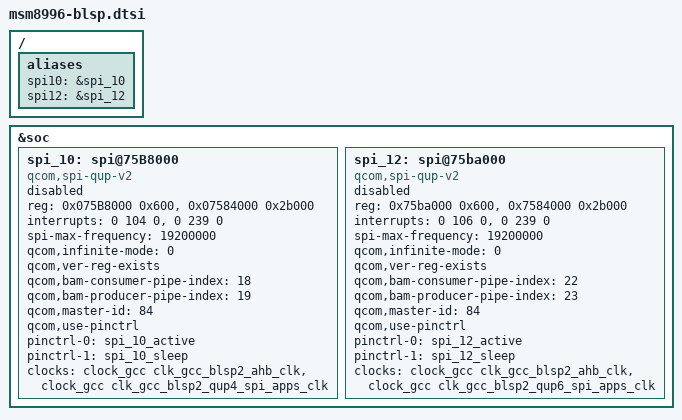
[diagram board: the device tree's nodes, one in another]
/*
 * Copyright (c) 2015, The Linux Foundation. All rights reserved.
 *
 * This program is free software; you can redistribute it and/or modify
 * it under the terms of the GNU General Public License version 2 and
 * only version 2 as published by the Free Software Foundation.
 *
 * This program is distributed in the hope that it will be useful,
 * but WITHOUT ANY WARRANTY; without even the implied warranty of
 * MERCHANTABILITY or FITNESS FOR A PARTICULAR PURPOSE.  See the
 * GNU General Public License for more details.
 */
/ {
	aliases {
		spi10 = &spi_10;
		spi12 = &spi_12;
	};
};

&soc {
	spi_10: spi@75B8000 { /* BLSP2 QUP4 */
		compatible = "qcom,spi-qup-v2";
		#address-cells = <1>;
		#size-cells = <0>;
		reg-names = "spi_physical", "spi_bam_physical";
		reg = <0x075B8000 0x600>,
		      <0x07584000 0x2b000>;
		interrupt-names = "spi_irq", "spi_bam_irq";
		interrupts = <0 104 0>, <0 239 0>;
		spi-max-frequency = <19200000>;
		qcom,infinite-mode = <0>;
		qcom,ver-reg-exists;

		qcom,bam-consumer-pipe-index = <18>;
		qcom,bam-producer-pipe-index = <19>;
		qcom,master-id = <84>;
		qcom,use-pinctrl;
		pinctrl-names = "spi_default", "spi_sleep";
		pinctrl-0 = <&spi_10_active>;
		pinctrl-1 = <&spi_10_sleep>;
		clock-names = "iface_clk", "core_clk";
		clocks = <&clock_gcc clk_gcc_blsp2_ahb_clk>,
			 <&clock_gcc clk_gcc_blsp2_qup4_spi_apps_clk>;
		status = "disabled";
	};

	spi_12: spi@75ba000 { /* BLSP2 QUP6 */
		compatible = "qcom,spi-qup-v2";
		#address-cells = <1>;
		#size-cells = <0>;
		reg-names = "spi_physical", "spi_bam_physical";
		reg = <0x75ba000 0x600>,
		      <0x7584000 0x2b000>;
		interrupt-names = "spi_irq", "spi_bam_irq";
		interrupts = <0 106 0>, <0 239 0>;
		spi-max-frequency = <19200000>;
		qcom,infinite-mode = <0>;
		qcom,ver-reg-exists;

		qcom,bam-consumer-pipe-index = <22>;
		qcom,bam-producer-pipe-index = <23>;
		qcom,master-id = <84>;
		qcom,use-pinctrl;
		pinctrl-names = "spi_default", "spi_sleep";
		pinctrl-0 = <&spi_12_active>;
		pinctrl-1 = <&spi_12_sleep>;
		clock-names = "iface_clk", "core_clk";
		clocks = <&clock_gcc clk_gcc_blsp2_ahb_clk>,
			 <&clock_gcc clk_gcc_blsp2_qup6_spi_apps_clk>;
		status = "disabled";
	};
};
